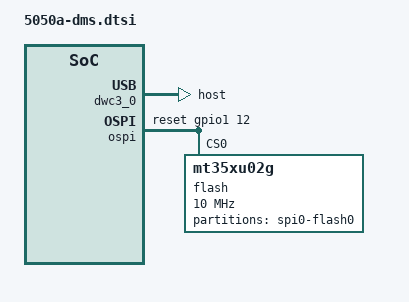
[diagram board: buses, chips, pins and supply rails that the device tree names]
// Copyright © Advanced Micro Devices, Inc., or its affiliates. All rights reserved.
// SPDX-License-Identifier: MIT
// Contributors: KC
// Maintainer: KC
#include "include/dt-bindings/gpio/gpio.h"
#include "include/dt-bindings/net/ti-dp83867.h"

&dwc3_0 { /* USB 2.0 host */
	dr_mode = "host";
	maximum-speed = "high-speed";
	snps,dis_u2_susphy_quirk;
	snps,dis_u3_susphy_quirk;
	snps,usb3_lpm_capable;
};

&ospi { /* PMC MIO0-10, 12, U297 MT35XU02G */
	compatible = "xlnx,versal-ospi-1.0", "cadence,qspi", "cdns,qspi-nor";
	bus-num = <2>;
	num-cs = <1>;
	#stream-id-cells = <1>;
	#address-cells = <1>;
	#size-cells = <0>;
	reset-gpios = <&gpio1 12 GPIO_ACTIVE_HIGH>;

	flash@0 {
		compatible = "mt35xu02g", "micron,m25p80", "jedec,spi-nor";
		reg = <0>;
		#address-cells = <1>;
		#size-cells = <1>;
		cdns,read-delay = <2>;
		cdns,tshsl-ns = <0>;
		cdns,tsd2d-ns = <0>;
		cdns,tchsh-ns = <1>;
		cdns,tslch-ns = <1>;
		spi-tx-bus-width = <8>;
		spi-rx-bus-width = <8>;
		spi-max-frequency = <10000000>;
		no-wp;
		partition@0 {
			label = "spi0-flash0";
			reg = <0 0x8000000>;
		};
	};
};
